# CFGS1 register map
Registers from a debugger description file.
Registers are 32-bit, access not given, no defined reset value unless marked. A register's access mark holds for its fields unless they carry their own. Addresses are absolute; registers are grouped by the start of their names; lines under a group give offsets from that group; [hi:lo] are bit positions; {n}, {i} and the like mark numbered series; 'fields as' and 'values as' point back to an identical list; <NAME> marks a mode.

## Level1
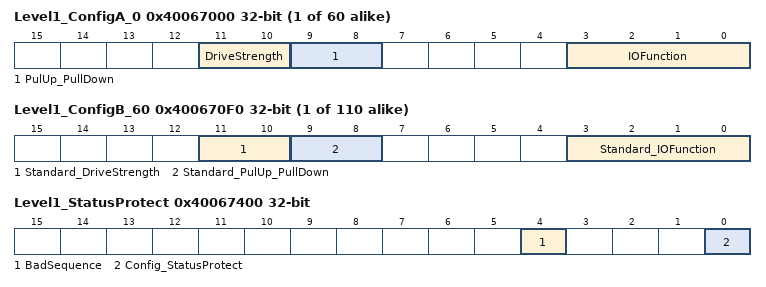
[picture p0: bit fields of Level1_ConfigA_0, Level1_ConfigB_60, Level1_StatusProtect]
{0x40067000+4i} Level1_ConfigA_{i} (i=0..59)
  [11:10] DriveStrength, [9:8] PulUp_PullDown, [3:0] IOFunction
{0x40067000+4i} Level1_ConfigB_{i} (i=60..169)
  [11:10] Standard_DriveStrength, [9:8] Standard_PulUp_PullDown, [3:0] Standard_IOFunction
0x40067400 Level1_StatusProtect
  [4] BadSequence, [0] Config_StatusProtect
